AUTOSAR XML
package /ECU
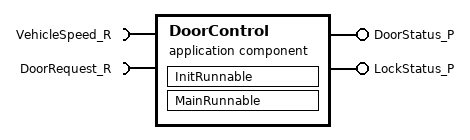
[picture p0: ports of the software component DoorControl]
  application sw component type DoorControl
    require port VehicleSpeed_R
    require port DoorRequest_R
    provide port DoorStatus_P
    provide port LockStatus_P
    swc-internal-behavior:
      runnable InitRunnable
      runnable MainRunnable
  data PreviousDoorState_IRV
